VERSION ""

NS_ :

BS_:

BU_:

BO_ 802 LDWS: 8 Vector__XXX
 SG_ state_of_LDWS : 0|4@1+ (1,0) [0|3] "" Vector__XXX

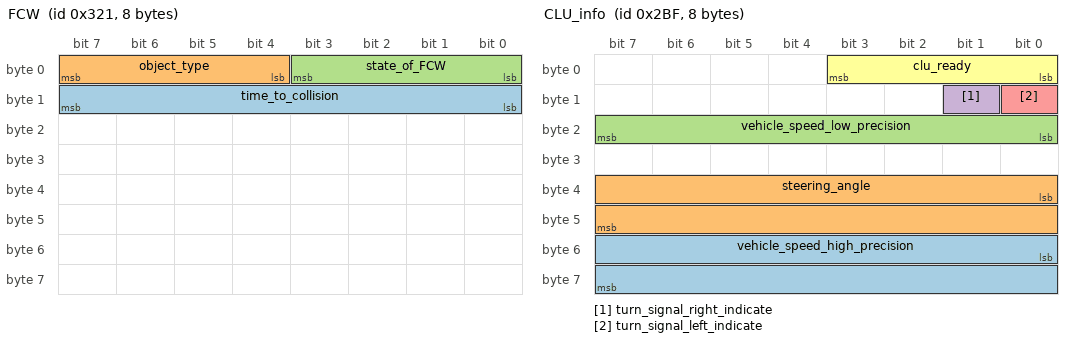
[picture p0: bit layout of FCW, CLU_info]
BO_ 801 FCW: 8 Vector__XXX
 SG_ time_to_collision : 8|8@1+ (0.1,0) [0|10] "" Vector__XXX
 SG_ object_type : 4|4@1+ (1,0) [0|2] "" Vector__XXX
 SG_ state_of_FCW : 0|4@1+ (1,0) [0|3] "" Vector__XXX

BO_ 800 DSM: 8 Vector__XXX
 SG_ state_of_DSM : 0|4@1+ (1,0) [0|3] "" Vector__XXX

BO_ 703 CLU_info: 8 Vector__XXX
 SG_ vehicle_speed_high_precision : 48|16@1+ (0.01,0) [0|150] "" Vector__XXX
 SG_ steering_angle : 32|16@1- (0.1,0) [-3276.8|3276.7] "" Vector__XXX
 SG_ vehicle_speed_low_precision : 16|8@1+ (1,0) [0|255] "" Vector__XXX
 SG_ turn_signal_right_indicate : 9|1@1+ (1,0) [0|1] "" Vector__XXX
 SG_ turn_signal_left_indicate : 8|1@1+ (1,0) [0|1] "" Vector__XXX
 SG_ clu_ready : 0|4@1+ (1,0) [0|7] "" Vector__XXX

BA_DEF_  "BusType" STRING ;
BA_DEF_DEF_  "BusType" "";
BA_ "BusType" "CAN";
